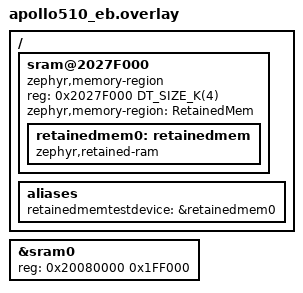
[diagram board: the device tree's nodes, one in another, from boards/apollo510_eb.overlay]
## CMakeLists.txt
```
#
# Copyright (c) 2023 Nordic Semiconductor ASA
#
# SPDX-License-Identifier: Apache-2.0
#

cmake_minimum_required(VERSION 3.28.0)
find_package(Zephyr REQUIRED HINTS $ENV{ZEPHYR_BASE})
project(retained_mem_api)

FILE(GLOB app_sources src/*.c)
target_sources(app PRIVATE ${app_sources})
```

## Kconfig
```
#
# Copyright (c) 2023, Nordic Semiconductor ASA
#
# SPDX-License-Identifier: Apache-2.0
#

mainmenu "Retained memory test"

config RETAINED_MEM_SIZE_LIMITED
	bool "Size limited test"
	help
	  Will limit data size for test to 1 byte instead of 10 bytes

source "Kconfig.zephyr"
```

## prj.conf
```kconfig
CONFIG_RETAINED_MEM=y
CONFIG_ZTEST=y
CONFIG_REBOOT=y

# Ensure test shuffling is not on, the `a_` prefixed test suite should run first to determine
# that the driver works across a reboot without the other tests interfering
CONFIG_ZTEST_SHUFFLE=n
```

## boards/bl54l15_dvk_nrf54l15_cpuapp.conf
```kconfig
# Copyright (c) 2024 Nordic Semiconductor ASA
# Copyright (c) 2025 Ezurio LLC
#
# SPDX-License-Identifier: Apache-2.0

CONFIG_POWEROFF=y
```

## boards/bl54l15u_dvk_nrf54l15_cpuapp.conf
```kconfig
#
# Copyright (c) 2024 Nordic Semiconductor ASA
# Copyright (c) 2025 Ezurio LLC
#
# SPDX-License-Identifier: Apache-2.0
#

CONFIG_POWEROFF=y
```

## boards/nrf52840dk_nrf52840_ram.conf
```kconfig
CONFIG_RETAINED_MEM_NRF_GPREGRET=n
```

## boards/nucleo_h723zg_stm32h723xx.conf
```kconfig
# SPDX-FileCopyrightText: Copyright The Zephyr Project Contributors
# SPDX-License-Identifier: Apache-2.0

CONFIG_STM32_BACKUP_SRAM_INIT_PRIORITY=40
```

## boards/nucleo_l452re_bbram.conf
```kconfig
CONFIG_RTC=y
```

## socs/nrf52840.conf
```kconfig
CONFIG_RETAINED_MEM_SIZE_LIMITED=y
```

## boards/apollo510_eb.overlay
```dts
/*
 * SSRAM start address of Apollo5xx is 0x20080000， and the size is 0x200000(2M)
 * Retained memory region is placed at the end of SSRAM
 * Retained memory size is 4KB
 */

/ {
	sram@2027F000 {
		compatible = "zephyr,memory-region", "mmio-sram";
		reg = <0x2027F000 DT_SIZE_K(4)>;
		zephyr,memory-region = "RetainedMem";
		status = "okay";

		retainedmem0: retainedmem {
			compatible = "zephyr,retained-ram";
			status = "okay";
		};
	};

	aliases {
		retainedmemtestdevice = &retainedmem0;
	};
};

&sram0 {
/* Shrink SRAM size to avoid overlap with retained memory region:
 * 2048 - 4 = 2044KB = 0x1FF000
 */
	reg = <0x20080000 0x1FF000>;
};
```

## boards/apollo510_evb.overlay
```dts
/*
 * SSRAM start address of Apollo5xx is 0x20080000,and the size is 0x180000(1536K)
 * Retained memory region is placed at the end of SSRAM
 * Retained memory size is 4KB
 */

/ {
	sram@201FF000 {
		compatible = "zephyr,memory-region", "mmio-sram";
		reg = <0x201FF000 DT_SIZE_K(4)>;
		zephyr,memory-region = "RetainedMem";
		status = "okay";

		retainedmem0: retainedmem {
			compatible = "zephyr,retained-ram";
			status = "okay";
		};
	};

	aliases {
		retainedmemtestdevice = &retainedmem0;
	};
};

&sram0 {
/* Shrink SRAM size to avoid overlap with retained memory region:
 * 1536 - 4 = 1532KB = 0x17F000
 */
	reg = <SSRAM_BASE_ADDR 0x17F000>;
};
```

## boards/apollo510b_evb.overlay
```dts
/*
 * SPDX-FileCopyrightText: 2025 Ambiq Micro Inc.
 *
 * SPDX-License-Identifier: Apache-2.0
 *
 * SSRAM start address of Apollo5xx is 0x20080000,and the size is 0x200000(2M)
 * Retained memory region is placed at the end of SSRAM
 * Retained memory size is 4KB
 */

/ {
	sram@2027F000 {
		compatible = "zephyr,memory-region", "mmio-sram";
		reg = <0x2027F000 DT_SIZE_K(4)>;
		zephyr,memory-region = "RetainedMem";
		status = "okay";

		retainedmem0: retainedmem {
			compatible = "zephyr,retained-ram";
			status = "okay";
		};
	};

	aliases {
		retainedmemtestdevice = &retainedmem0;
	};
};

&sram0 {
	/* Shrink SRAM size to avoid overlap with retained memory region:
	 * 2048 - 4 = 2044KB = 0x1FF000
	 */
	reg = <0x20080000 0x1FF000>;
};
```

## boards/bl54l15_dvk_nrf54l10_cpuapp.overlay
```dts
/*
 * Copyright (c) 2024 Nordic Semiconductor ASA
 * Copyright (c) 2025 Ezurio LLC
 *
 * SPDX-License-Identifier: Apache-2.0
 */

/ {
	cpuapp_sram@2002f000 {
		compatible = "zephyr,memory-region", "mmio-sram";
		reg = <0x2002f000 DT_SIZE_K(4)>;
		zephyr,memory-region = "RetainedMem";
		status = "okay";

		retainedmem0: retainedmem {
			compatible = "zephyr,retained-ram";
			status = "okay";
		};
	};

	aliases {
		retainedmemtestdevice = &retainedmem0;
	};
};

&cpuapp_sram {
	/* Shrink SRAM size to avoid overlap with retained memory region:
	 * 192 - 4 = 188KB = 0x2f000
	 */
	reg = <0x20000000 0x2f000>;
	ranges = <0x0 0x20000000 0x2f000>;
};
```

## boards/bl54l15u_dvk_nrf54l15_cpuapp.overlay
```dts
/*
 * Copyright (c) 2024 Nordic Semiconductor ASA
 * Copyright (c) 2025 Ezurio LLC
 *
 * SPDX-License-Identifier: Apache-2.0
 */

/ {
	cpuapp_sram@2002e000 {
		compatible = "zephyr,memory-region", "mmio-sram";
		reg = <0x2002e000 DT_SIZE_K(4)>;
		zephyr,memory-region = "RetainedMem";
		status = "okay";

		retainedmem0: retainedmem {
			compatible = "zephyr,retained-ram";
			status = "okay";
		};
	};

	aliases {
		retainedmemtestdevice = &retainedmem0;
	};
};

&cpuapp_sram {
	reg = <0x20000000 DT_SIZE_K(184)>;
	ranges = <0x0 0x20000000 0x2e000>;
};
```

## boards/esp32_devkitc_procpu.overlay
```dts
/*
 * Copyright (c) 2025 Espressif Systems (Shanghai) Co., Ltd.
 *
 * SPDX-License-Identifier: Apache-2.0
 */

/ {
	memory@50001f00 {
		compatible = "zephyr,memory-region", "mmio-sram";
		reg = <0x50001f00 0x100>;
		ranges = <0x0 0x50001f00 0x100>;
		zephyr,memory-region = "RTC_SLOW_RAM_RETAINED_MEM";
		status = "okay";
		#address-cells = <1>;
		#size-cells = <1>;

		retainedmem0: retainedmem {
			compatible = "zephyr,retained-ram";
			status = "okay";
			ranges;
			#address-cells = <1>;
			#size-cells = <1>;
		};
	};

	aliases {
		retainedmemtestdevice = &retainedmem0;
	};
};

&rtc_slow_ram {
	/* Shrink rtc_slow_ram size to avoid overlap with retained memory region:
	 * 8KB - 256 = 0x1f00
	 */
	reg = <0x50000000 0x1f00>;
};
```

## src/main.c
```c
/*
 * Copyright (c) 2023, Nordic Semiconductor ASA
 *
 * SPDX-License-Identifier: Apache-2.0
 */
#include <zephyr/cache.h>
#include <zephyr/drivers/retained_mem.h>
#include <zephyr/ztest.h>
#include <errno.h>
#include <zephyr/sys/reboot.h>

const static struct device *retained_mem_test_device =	DEVICE_DT_GET(DT_ALIAS(
									retainedmemtestdevice));

#define TEST_STATUS_NORMAL 0x0
#define TEST_STATUS_REBOOT 0x1b83
volatile uint32_t test_status __attribute__((section(".noinit.test")));

#if CONFIG_RETAINED_MEM_SIZE_LIMITED
/* For size-limited tests, use data size of 1 byte */
static uint8_t data[1] = {
	0x5b,
};
static uint8_t empty_data[1] = {
	0x00,
};
static uint8_t reboot_data[1] = {
	0xe8,
};
static uint8_t buffer[1];
#else
/* For other devices, use data size of 10 bytes */
static uint8_t data[10] = {
	0x23, 0x82, 0xa8, 0x7b, 0xde, 0x18, 0x00, 0xff, 0x8e, 0xd6,
};
static uint8_t empty_data[10] = {
	0x00, 0x00, 0x00, 0x00, 0x00, 0x00, 0x00, 0x00, 0x00, 0x00,
};
static uint8_t reboot_data[10] = {
	0xf1, 0xb2, 0x13, 0x00, 0xff, 0x22, 0x3f, 0x1b, 0x58, 0xab,
};
static uint8_t buffer[10];
#endif

ZTEST(retained_mem_api, test_read_write)
{
	int32_t rc;

	rc = retained_mem_write(retained_mem_test_device, 0, data, sizeof(data));
	zassert_equal(rc, 0, "Return code should be success");

	memset(buffer, 0, sizeof(buffer));

	rc = retained_mem_read(retained_mem_test_device, 0, buffer, sizeof(buffer));
	zassert_equal(rc, 0, "Return code should be success");

	zassert_mem_equal(data, buffer, sizeof(data), "Expected written data to match");
}

ZTEST(retained_mem_api, test_size)
{
	int32_t rc;

	rc = retained_mem_size(retained_mem_test_device);
	zassume_between_inclusive(rc, 1, 0x4000, "Retained memory size is not valid");
}

ZTEST(retained_mem_api, test_clear)
{
	int32_t rc;

	rc = retained_mem_clear(retained_mem_test_device);
	zassert_equal(rc, 0, "Return code should be success");

	rc = retained_mem_write(retained_mem_test_device, 0, data, sizeof(data));
	zassert_equal(rc, 0, "Return code should be success");

	rc = retained_mem_read(retained_mem_test_device, 0, buffer, sizeof(buffer));
	zassert_equal(rc, 0, "Return code should be success");

	zassert_mem_equal(data, buffer, sizeof(data), "Expected written data to match");

	rc = retained_mem_clear(retained_mem_test_device);
	zassert_equal(rc, 0, "Return code should be success");

	rc = retained_mem_read(retained_mem_test_device, 0, buffer, sizeof(buffer));
	zassert_equal(rc, 0, "Return code should be success");

	zassert_mem_equal(empty_data, buffer, sizeof(empty_data), "Expected data to be 0x00's");
}

ZTEST(a_retained_mem_api_reboot, test_reboot)
{
	int32_t rc;

	if (test_status == TEST_STATUS_REBOOT) {
		test_status = TEST_STATUS_NORMAL;

		rc = retained_mem_read(retained_mem_test_device, 0, buffer, sizeof(buffer));
		zassert_equal(rc, 0, "Return code should be success");

		rc = retained_mem_clear(retained_mem_test_device);
		zassert_equal(rc, 0, "Return code should be success");

		zassert_mem_equal(reboot_data, buffer, sizeof(reboot_data),
				  "Expected written data to match over reboot");
	} else {
		rc = retained_mem_clear(retained_mem_test_device);
		zassert_equal(rc, 0, "Return code should be success");

		rc = retained_mem_write(retained_mem_test_device, 0, reboot_data,
					sizeof(reboot_data));
		zassert_equal(rc, 0, "Return code should be success");

		test_status = TEST_STATUS_REBOOT;
		sys_cache_data_flush_range((void *)(uintptr_t)&test_status, sizeof(test_status));

		sys_reboot(SYS_REBOOT_COLD);
	}
}

/* Use 2 tests so that the reboot test does not get interrupted with another test after reboot */
ZTEST_SUITE(a_retained_mem_api_reboot, NULL, NULL, NULL, NULL, NULL);
ZTEST_SUITE(retained_mem_api, NULL, NULL, NULL, NULL, NULL);
```
